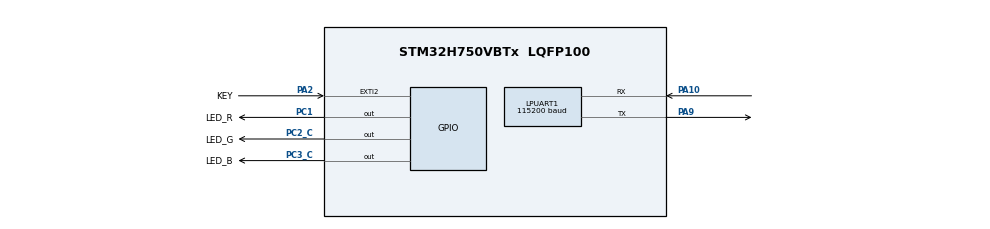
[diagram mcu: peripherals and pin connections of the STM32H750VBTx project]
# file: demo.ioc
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Bdma.LPUART1_RX.0.Direction=DMA_PERIPH_TO_MEMORY
Bdma.LPUART1_RX.0.EventEnable=DISABLE
Bdma.LPUART1_RX.0.Instance=BDMA_Channel0
Bdma.LPUART1_RX.0.MemDataAlignment=DMA_MDATAALIGN_BYTE
Bdma.LPUART1_RX.0.MemInc=DMA_MINC_ENABLE
Bdma.LPUART1_RX.0.Mode=DMA_NORMAL
Bdma.LPUART1_RX.0.PeriphDataAlignment=DMA_PDATAALIGN_BYTE
Bdma.LPUART1_RX.0.PeriphInc=DMA_PINC_DISABLE
Bdma.LPUART1_RX.0.Polarity=HAL_DMAMUX_REQ_GEN_RISING
Bdma.LPUART1_RX.0.Priority=DMA_PRIORITY_LOW
Bdma.LPUART1_RX.0.RequestNumber=1
Bdma.LPUART1_RX.0.SignalID=NONE
Bdma.LPUART1_RX.0.SyncEnable=DISABLE
Bdma.LPUART1_RX.0.SyncPolarity=HAL_DMAMUX_SYNC_NO_EVENT
Bdma.LPUART1_RX.0.SyncRequestNumber=1
Bdma.LPUART1_RX.0.SyncSignalID=NONE
Bdma.LPUART1_TX.1.Direction=DMA_MEMORY_TO_PERIPH
Bdma.LPUART1_TX.1.EventEnable=DISABLE
Bdma.LPUART1_TX.1.Instance=BDMA_Channel1
Bdma.LPUART1_TX.1.MemDataAlignment=DMA_MDATAALIGN_BYTE
Bdma.LPUART1_TX.1.MemInc=DMA_MINC_ENABLE
Bdma.LPUART1_TX.1.Mode=DMA_NORMAL
Bdma.LPUART1_TX.1.PeriphDataAlignment=DMA_PDATAALIGN_BYTE
Bdma.LPUART1_TX.1.PeriphInc=DMA_PINC_DISABLE
Bdma.LPUART1_TX.1.Polarity=HAL_DMAMUX_REQ_GEN_RISING
Bdma.LPUART1_TX.1.Priority=DMA_PRIORITY_LOW
Bdma.LPUART1_TX.1.RequestNumber=1
Bdma.LPUART1_TX.1.SignalID=NONE
Bdma.LPUART1_TX.1.SyncEnable=DISABLE
Bdma.LPUART1_TX.1.SyncPolarity=HAL_DMAMUX_SYNC_NO_EVENT
Bdma.LPUART1_TX.1.SyncRequestNumber=1
Bdma.LPUART1_TX.1.SyncSignalID=NONE
Bdma.Request0=LPUART1_RX
Bdma.Request1=LPUART1_TX
Bdma.RequestsNb=2
CORTEX_M7.default_mode_Activation=1
LPUART1.BaudRate=115200
Mcu.Family=STM32H7
Mcu.Name=STM32H750VBTx
Mcu.Package=LQFP100
NVIC.BDMA_Channel0_IRQn=true\:0\:0\:false\:false\:true\:false\:true\:true
NVIC.BDMA_Channel1_IRQn=true\:0\:0\:false\:false\:true\:false\:true\:true
NVIC.EXTI2_IRQn=true\:0\:0\:false\:false\:true\:true\:true\:true
NVIC.LPUART1_IRQn=true\:0\:0\:false\:false\:true\:true\:true\:true
NVIC.PriorityGroup=NVIC_PRIORITYGROUP_4
PA10.GPIO_PuPd=GPIO_PULLUP
PA10.GPIO_Speed=GPIO_SPEED_FREQ_HIGH
PA10.Mode=Asynchronous
PA10.Signal=LPUART1_RX
PA13\ (JTMS/SWDIO).Mode=Serial_Wire
PA13\ (JTMS/SWDIO).Signal=DEBUG_JTMS-SWDIO
PA14\ (JTCK/SWCLK).Mode=Serial_Wire
PA14\ (JTCK/SWCLK).Signal=DEBUG_JTCK-SWCLK
PA2.GPIO_Label=KEY
PA2.GPIO_ModeDefaultEXTI=GPIO_MODE_IT_RISING_FALLING
PA2.GPIO_PuPd=GPIO_PULLUP
PA2.Signal=GPXTI2
PA9.GPIO_PuPd=GPIO_PULLUP
PA9.GPIO_Speed=GPIO_SPEED_FREQ_VERY_HIGH
PA9.Mode=Asynchronous
PA9.Signal=LPUART1_TX
PC1.GPIO_Label=LED_R
PC1.GPIO_ModeDefaultOutputPP=GPIO_MODE_OUTPUT_PP
PC1.GPIO_PuPd=GPIO_PULLUP
PC1.GPIO_Speed=GPIO_SPEED_FREQ_VERY_HIGH
PC1.PinState=GPIO_PIN_SET
PC1.Signal=GPIO_Output
PC14-OSC32_IN\ (OSC32_IN).Mode=LSE-External-Oscillator
PC14-OSC32_IN\ (OSC32_IN).Signal=RCC_OSC32_IN
PC15-OSC32_OUT\ (OSC32_OUT).Mode=LSE-External-Oscillator
PC15-OSC32_OUT\ (OSC32_OUT).Signal=RCC_OSC32_OUT
PC2_C.GPIO_Label=LED_G
PC2_C.GPIO_ModeDefaultOutputPP=GPIO_MODE_OUTPUT_PP
PC2_C.GPIO_PuPd=GPIO_PULLUP
PC2_C.GPIO_Speed=GPIO_SPEED_FREQ_VERY_HIGH
PC2_C.PinState=GPIO_PIN_SET
PC2_C.Signal=GPIO_Output
PC3_C.GPIO_Label=LED_B
PC3_C.GPIO_ModeDefaultOutputPP=GPIO_MODE_OUTPUT_PP
PC3_C.GPIO_PuPd=GPIO_PULLUP
PC3_C.GPIO_Speed=GPIO_SPEED_FREQ_VERY_HIGH
PC3_C.PinState=GPIO_PIN_SET
PC3_C.Signal=GPIO_Output
PH0-OSC_IN\ (PH0).Mode=HSE-External-Oscillator
PH0-OSC_IN\ (PH0).Signal=RCC_OSC_IN
PH1-OSC_OUT\ (PH1).Mode=HSE-External-Oscillator
PH1-OSC_OUT\ (PH1).Signal=RCC_OSC_OUT
ProjectManager.HeapSize=0x200
ProjectManager.StackSize=0x400
ProjectManager.TargetToolchain=MDK-ARM V5
RCC.ADCFreq_Value=50390625
RCC.APB1Freq_Value=120000000
RCC.APB2Freq_Value=120000000
RCC.APB3Freq_Value=120000000
RCC.APB4Freq_Value=120000000
RCC.CortexFreq_Value=480000000
RCC.D1PPRE=RCC_APB3_DIV2
RCC.D2PPRE1=RCC_APB1_DIV2
RCC.D2PPRE2=RCC_APB2_DIV2
RCC.D3PPRE=RCC_APB4_DIV2
RCC.DIVM1=5
RCC.DIVN1=192
RCC.HCLKFreq_Value=240000000
RCC.HPRE=RCC_HCLK_DIV2
RCC.PLLFRACN=0
RCC.PLLSourceVirtual=RCC_PLLSOURCE_HSE
RCC.SYSCLKFreq_VALUE=480000000
RCC.SYSCLKSource=RCC_SYSCLKSOURCE_PLLCLK
RCC.USBFreq_Value=480000000
VP_MEMORYMAP_VS_MEMORYMAP.Mode=CurAppReg
board=custom

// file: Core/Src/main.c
/* USER CODE BEGIN Header */
/**
  ******************************************************************************
  * @file           : main.c
  * @brief          : Main program body
  ******************************************************************************
  * @attention
  *
  * Copyright (c) 2024 STMicroelectronics.
  * All rights reserved.
  *
  * This software is licensed under terms that can be found in the LICENSE file
  * in the root directory of this software component.
  * If no LICENSE file comes with this software, it is provided AS-IS.
  *
  ******************************************************************************
  */
/* USER CODE END Header */
#include "main.h"
#include "bdma.h"
#include "usart.h"
#include "memorymap.h"
#include "gpio.h"

/* USER CODE BEGIN Includes */
#include "drv_include.h"
/* USER CODE END Includes */

void SystemClock_Config(void);
static void MPU_Config(void);

int main(void)
{

  /* MPU Configuration--------------------------------------------------------*/
  MPU_Config();

  /* MCU Configuration--------------------------------------------------------*/

  /* Reset of all peripherals, Initializes the Flash interface and the Systick. */
  HAL_Init();

  /* Configure the system clock */
  SystemClock_Config();

  /* Initialize all configured peripherals */
  MX_GPIO_Init();
  MX_BDMA_Init();
  MX_LPUART1_UART_Init();
  /* USER CODE BEGIN 2 */
	drv_init();
  /* USER CODE END 2 */

  /* Infinite loop */
  while (1)
  {

    /* USER CODE BEGIN 3 */
//		LED_R_SET(KEY_STATUS_IRQ == KEY_ON ? LED_ON : LED_OFF);
		drv_lpuart1_poll();
  }
  /* USER CODE END 3 */
}

void SystemClock_Config(void)
{
  RCC_OscInitTypeDef RCC_OscInitStruct = {0};
  RCC_ClkInitTypeDef RCC_ClkInitStruct = {0};

  /** Supply configuration update enable
  */
  HAL_PWREx_ConfigSupply(PWR_LDO_SUPPLY);

  /** Configure the main internal regulator output voltage
  */
  __HAL_PWR_VOLTAGESCALING_CONFIG(PWR_REGULATOR_VOLTAGE_SCALE1);

  while(!__HAL_PWR_GET_FLAG(PWR_FLAG_VOSRDY)) {}

  __HAL_RCC_SYSCFG_CLK_ENABLE();
  __HAL_PWR_VOLTAGESCALING_CONFIG(PWR_REGULATOR_VOLTAGE_SCALE0);

  while(!__HAL_PWR_GET_FLAG(PWR_FLAG_VOSRDY)) {}

  /** Initializes the RCC Oscillators according to the specified parameters
  * in the RCC_OscInitTypeDef structure.
  */
  RCC_OscInitStruct.OscillatorType = RCC_OSCILLATORTYPE_HSE;
  RCC_OscInitStruct.HSEState = RCC_HSE_ON;
  RCC_OscInitStruct.PLL.PLLState = RCC_PLL_ON;
  RCC_OscInitStruct.PLL.PLLSource = RCC_PLLSOURCE_HSE;
  RCC_OscInitStruct.PLL.PLLM = 5;
  RCC_OscInitStruct.PLL.PLLN = 192;
  RCC_OscInitStruct.PLL.PLLP = 2;
  RCC_OscInitStruct.PLL.PLLQ = 2;
  RCC_OscInitStruct.PLL.PLLR = 2;
  RCC_OscInitStruct.PLL.PLLRGE = RCC_PLL1VCIRANGE_2;
  RCC_OscInitStruct.PLL.PLLVCOSEL = RCC_PLL1VCOWIDE;
  RCC_OscInitStruct.PLL.PLLFRACN = 0;
  if (HAL_RCC_OscConfig(&RCC_OscInitStruct) != HAL_OK)
  {
    Error_Handler();
  }

  /** Initializes the CPU, AHB and APB buses clocks
  */
  RCC_ClkInitStruct.ClockType = RCC_CLOCKTYPE_HCLK|RCC_CLOCKTYPE_SYSCLK
                              |RCC_CLOCKTYPE_PCLK1|RCC_CLOCKTYPE_PCLK2
                              |RCC_CLOCKTYPE_D3PCLK1|RCC_CLOCKTYPE_D1PCLK1;
  RCC_ClkInitStruct.SYSCLKSource = RCC_SYSCLKSOURCE_PLLCLK;
  RCC_ClkInitStruct.SYSCLKDivider = RCC_SYSCLK_DIV1;
  RCC_ClkInitStruct.AHBCLKDivider = RCC_HCLK_DIV2;
  RCC_ClkInitStruct.APB3CLKDivider = RCC_APB3_DIV2;
  RCC_ClkInitStruct.APB1CLKDivider = RCC_APB1_DIV2;
  RCC_ClkInitStruct.APB2CLKDivider = RCC_APB2_DIV2;
  RCC_ClkInitStruct.APB4CLKDivider = RCC_APB4_DIV2;

  if (HAL_RCC_ClockConfig(&RCC_ClkInitStruct, FLASH_LATENCY_4) != HAL_OK)
  {
    Error_Handler();
  }
}

 /* MPU Configuration */

void MPU_Config(void)
{
  MPU_Region_InitTypeDef MPU_InitStruct = {0};

  /* Disables the MPU */
  HAL_MPU_Disable();

  /** Initializes and configures the Region and the memory to be protected
  */
  MPU_InitStruct.Enable = MPU_REGION_ENABLE;
  MPU_InitStruct.Number = MPU_REGION_NUMBER0;
  MPU_InitStruct.BaseAddress = 0x0;
  MPU_InitStruct.Size = MPU_REGION_SIZE_4GB;
  MPU_InitStruct.SubRegionDisable = 0x87;
  MPU_InitStruct.TypeExtField = MPU_TEX_LEVEL0;
  MPU_InitStruct.AccessPermission = MPU_REGION_NO_ACCESS;
  MPU_InitStruct.DisableExec = MPU_INSTRUCTION_ACCESS_DISABLE;
  MPU_InitStruct.IsShareable = MPU_ACCESS_SHAREABLE;
  MPU_InitStruct.IsCacheable = MPU_ACCESS_NOT_CACHEABLE;
  MPU_InitStruct.IsBufferable = MPU_ACCESS_NOT_BUFFERABLE;

  HAL_MPU_ConfigRegion(&MPU_InitStruct);
  /* Enables the MPU */
  HAL_MPU_Enable(MPU_PRIVILEGED_DEFAULT);

}

void Error_Handler(void)
{
  __disable_irq();
  while (1)
  {
  }
}
